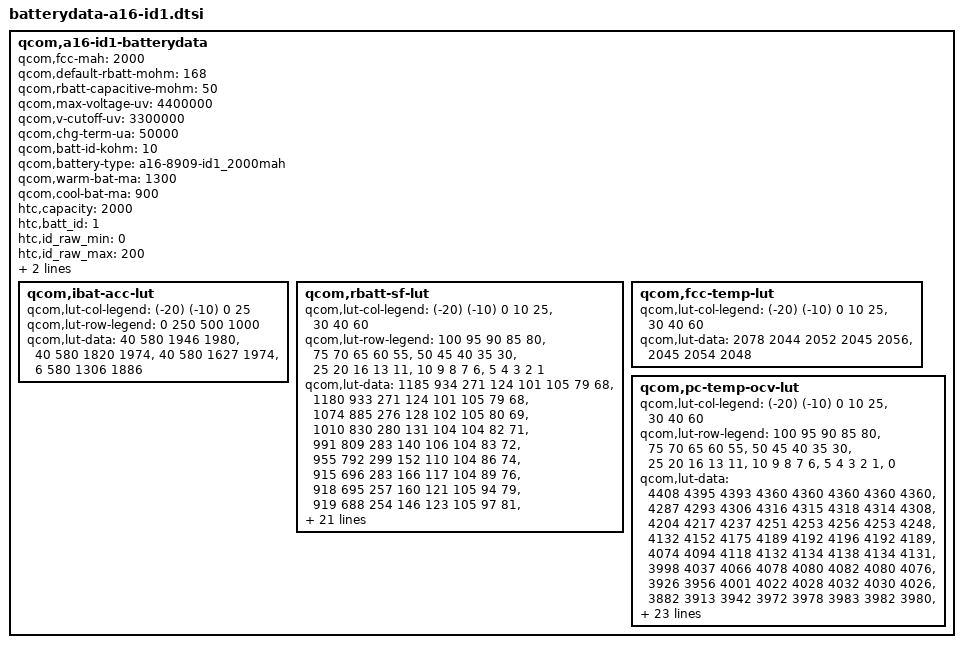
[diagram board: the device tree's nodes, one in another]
/* Copyright (c) 2013, The Linux Foundation. All rights reserved.
 *
 * This program is free software; you can redistribute it and/or modify
 * it under the terms of the GNU General Public License version 2 and
 * only version 2 as published by the Free Software Foundation.
 *
 * This program is distributed in the hope that it will be useful,
 * but WITHOUT ANY WARRANTY; without even the implied warranty of
 * MERCHANTABILITY or FITNESS FOR A PARTICULAR PURPOSE.  See the
 * GNU General Public License for more details.
 */

qcom,a16-id1-batterydata {
	qcom,fcc-mah = <2000>;
	qcom,default-rbatt-mohm = <168>;
	qcom,rbatt-capacitive-mohm = <50>;
	qcom,max-voltage-uv = <4400000>;
	qcom,v-cutoff-uv = <3300000>;
	qcom,chg-term-ua = <50000>;
	qcom,batt-id-kohm = <10>;
	qcom,battery-type = "a16-8909-id1_2000mah";
	qcom,warm-bat-ma = <1300>;
	qcom,cool-bat-ma = <900>;
	htc,capacity = <2000>;
	htc,batt_id = <1>;
	htc,id_raw_min = <0>;
	htc,id_raw_max = <200>;
	htc,type = <1>;
	htc,model_name = "B0PKX100";

	qcom,ibat-acc-lut {
		qcom,lut-col-legend = <(-20) (-10) 0 25>;
		qcom,lut-row-legend = <0 250 500 1000>;
		qcom,lut-data = <40 580 1946 1980>,
				<40 580 1820 1974>,
				<40 580 1627 1974>,
				<6 580 1306 1886>;
	};

	qcom,rbatt-sf-lut {
		qcom,lut-col-legend = <(-20) (-10) 0 10 25>,
				<30 40 60>;
		qcom,lut-row-legend = <100 95 90 85 80>,
				<75 70 65 60 55>,
				<50 45 40 35 30>,
				<25 20 16 13 11>,
				<10 9 8 7 6>,
				<5 4 3 2 1>;
		qcom,lut-data = <1185 934 271 124 101 105 79 68>,
				<1180 933 271 124 101 105 79 68>,
				<1074 885 276 128 102 105 80 69>,
				<1010 830 280 131 104 104 82 71>,
				<991 809 283 140 106 104 83 72>,
				<955 792 299 152 110 104 86 74>,
				<915 696 283 166 117 104 89 76>,
				<918 695 257 160 121 105 94 79>,
				<919 688 254 146 123 105 97 81>,
				<947 694 250 114 105 106 88 75>,
				<999 732 249 104 98 106 79 70>,
				<1074 795 250 104 98 107 80 71>,
				<1169 872 263 105 99 108 83 73>,
				<1290 986 291 114 101 109 86 76>,
				<1457 1128 338 132 102 110 83 75>,
				<1812 1284 413 162 105 112 80 68>,
				<2434 1466 520 209 108 113 82 70>,
				<3218 1660 635 274 114 114 83 71>,
				<3898 1864 727 344 118 115 85 71>,
				<5040 2019 801 382 119 116 83 70>,
				<5836 2323 868 432 124 116 85 72>,
				<6837 2796 946 496 131 116 88 74>,
				<8195 3410 1039 578 140 117 92 76>,
				<10071 4296 1149 686 154 118 95 77>,
				<12708 5670 1303 860 170 120 98 78>,
				<16546 7744 1611 1073 186 122 98 76>,
				<22712 11142 2169 1364 218 123 102 78>,
				<33780 18356 3195 1904 279 126 111 82>,
				<54755 32206 5193 3242 381 129 125 91>,
				<95199 60514 9269 6044 580 132 158 115>;
	};

	qcom,fcc-temp-lut {
		qcom,lut-col-legend = <(-20) (-10) 0 10 25>,
				<30 40 60>;
		qcom,lut-data = <2078 2044 2052 2045 2056>,
				<2045 2054 2048>;
	};

	qcom,pc-temp-ocv-lut {
		qcom,lut-col-legend = <(-20) (-10) 0 10 25>,
				<30 40 60>;
		qcom,lut-row-legend = <100 95 90 85 80>,
				<75 70 65 60 55>,
				<50 45 40 35 30>,
				<25 20 16 13 11>,
				<10 9 8 7 6>,
				<5 4 3 2 1>,
				<0>;
		qcom,lut-data = <4408 4395 4393 4360 4360 4360 4360 4360>,
				<4287 4293 4306 4316 4315 4318 4314 4308>,
				<4204 4217 4237 4251 4253 4256 4253 4248>,
				<4132 4152 4175 4189 4192 4196 4192 4189>,
				<4074 4094 4118 4132 4134 4138 4134 4131>,
				<3998 4037 4066 4078 4080 4082 4080 4076>,
				<3926 3956 4001 4022 4028 4032 4030 4026>,
				<3882 3913 3942 3972 3978 3983 3982 3980>,
				<3842 3868 3898 3924 3935 3939 3938 3936>,
				<3820 3834 3860 3875 3883 3886 3888 3886>,
				<3806 3815 3827 3840 3846 3849 3848 3848>,
				<3793 3802 3803 3814 3820 3822 3823 3822>,
				<3781 3792 3790 3794 3800 3802 3802 3802>,
				<3768 3781 3782 3782 3784 3786 3786 3784>,
				<3753 3768 3772 3774 3771 3771 3770 3764>,
				<3736 3752 3760 3762 3758 3755 3750 3737>,
				<3717 3730 3741 3743 3738 3735 3730 3716>,
				<3698 3712 3718 3720 3717 3714 3710 3697>,
				<3681 3696 3698 3698 3696 3694 3690 3678>,
				<3666 3686 3682 3682 3683 3682 3679 3668>,
				<3657 3680 3678 3678 3680 3679 3677 3667>,
				<3646 3675 3672 3674 3678 3677 3675 3665>,
				<3634 3668 3668 3670 3674 3674 3672 3662>,
				<3620 3660 3662 3664 3670 3670 3668 3658>,
				<3600 3650 3654 3657 3661 3662 3658 3646>,
				<3572 3634 3639 3640 3637 3638 3633 3617>,
				<3532 3598 3602 3598 3593 3592 3588 3570>,
				<3474 3538 3546 3540 3534 3531 3528 3508>,
				<3394 3455 3468 3460 3453 3450 3448 3426>,
				<3274 3328 3351 3336 3333 3326 3327 3298>,
				<3000 3000 3000 3000 3000 3000 3000 3000>;
	};
};
